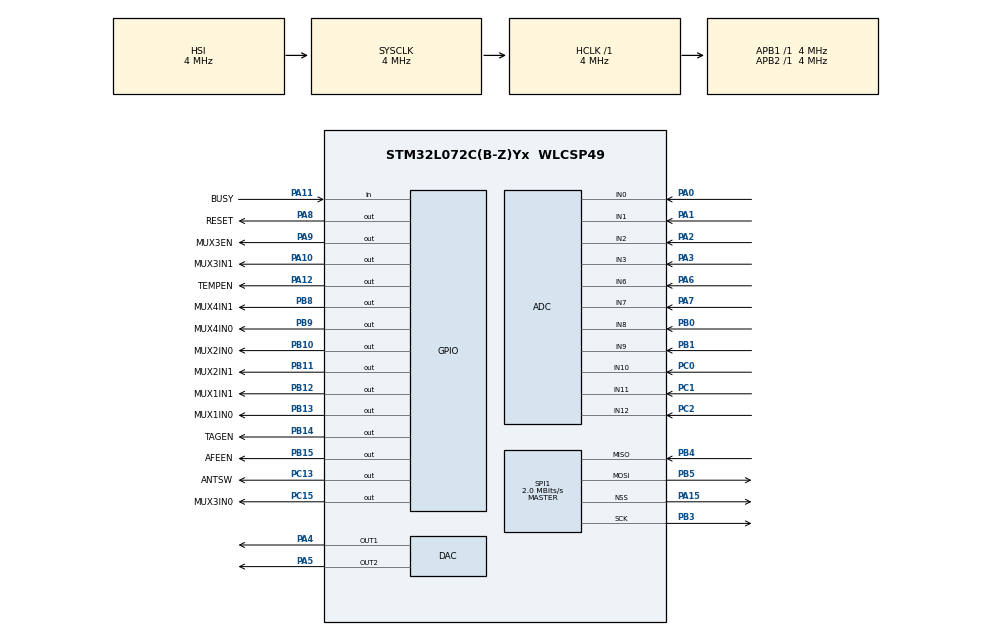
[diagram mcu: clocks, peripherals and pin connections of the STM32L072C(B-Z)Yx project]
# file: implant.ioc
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Mcu.Family=STM32L0
Mcu.Name=STM32L072C(B-Z)Yx
Mcu.Package=WLCSP49
PA0.Mode=IN0
PA0.Signal=ADC_IN0
PA1.Mode=IN1
PA1.Signal=ADC_IN1
PA10.GPIO_Label=MUX3IN1
PA10.Signal=GPIO_Output
PA11.GPIO_Label=BUSY
PA11.Signal=GPIO_Input
PA12.GPIO_Label=TEMPEN
PA12.Signal=GPIO_Output
PA13.Mode=Serial_Wire
PA13.Signal=SYS_SWDIO
PA14.Mode=Serial_Wire
PA14.Signal=SYS_SWCLK
PA15.Mode=NSS_Signal_Hard_Output
PA15.Signal=SPI1_NSS
PA2.Mode=IN2
PA2.Signal=ADC_IN2
PA3.Mode=IN3
PA3.Signal=ADC_IN3
PA4.Signal=COMP_DAC1_group
PA5.Signal=COMP_DAC2_group
PA6.Mode=IN6
PA6.Signal=ADC_IN6
PA7.Mode=IN7
PA7.Signal=ADC_IN7
PA8.GPIO_Label=RESET
PA8.Signal=GPIO_Output
PA9.GPIO_Label=MUX3EN
PA9.Signal=GPIO_Output
PB0.Mode=IN8
PB0.Signal=ADC_IN8
PB1.Mode=IN9
PB1.Signal=ADC_IN9
PB10.GPIO_Label=MUX2IN0
PB10.Signal=GPIO_Output
PB11.GPIO_Label=MUX2IN1
PB11.Signal=GPIO_Output
PB12.GPIO_Label=MUX1IN1
PB12.Signal=GPIO_Output
PB13.GPIO_Label=MUX1IN0
PB13.Signal=GPIO_Output
PB14.GPIO_Label=TAGEN
PB14.GPIO_ModeDefaultOutputPP=GPIO_MODE_OUTPUT_OD
PB14.PinState=GPIO_PIN_SET
PB14.Signal=GPIO_Output
PB15.GPIO_Label=AFEEN
PB15.Signal=GPIO_Output
PB3.Mode=Full_Duplex_Master
PB3.Signal=SPI1_SCK
PB4.Mode=Full_Duplex_Master
PB4.Signal=SPI1_MISO
PB5.Mode=Full_Duplex_Master
PB5.Signal=SPI1_MOSI
PB8.GPIO_Label=MUX4IN1
PB8.Signal=GPIO_Output
PB9.GPIO_Label=MUX4IN0
PB9.Signal=GPIO_Output
PC0.Mode=IN10
PC0.Signal=ADC_IN10
PC1.Mode=IN11
PC1.Signal=ADC_IN11
PC13.GPIO_Label=ANTSW
PC13.Signal=GPIO_Output
PC15-OSC32_OUT.GPIO_Label=MUX3IN0
PC15-OSC32_OUT.Signal=GPIO_Output
PC2.Mode=IN12
PC2.Signal=ADC_IN12
ProjectManager.HeapSize=0x200
ProjectManager.StackSize=0x400
ProjectManager.TargetToolchain=Makefile
RCC.ADCFreq_Value=4000000
RCC.AHBFreq_Value=4000000
RCC.APB1Freq_Value=4000000
RCC.APB1TimFreq_Value=4000000
RCC.APB2Freq_Value=4000000
RCC.APB2TimFreq_Value=4000000
RCC.HCLKFreq_Value=4000000
RCC.HSE_VALUE=8000000
RCC.HSI16_VALUE=16000000
RCC.HSI48_VALUE=48000000
RCC.HSIRCDiv=4
RCC.HSI_VALUE=4000000
RCC.LSE_VALUE=32768
RCC.MSI_VALUE=2097000
RCC.SYSCLKFreq_VALUE=4000000
RCC.SYSCLKSource=RCC_SYSCLKSOURCE_HSI
RCC.VCOOutputFreq_Value=12000000
SH.COMP_DAC1_group.0=DAC_OUT1,DAC_OUT1
SH.COMP_DAC2_group.0=DAC_OUT2,DAC_OUT2
SPI1.CalculateBaudRate=2.0 MBits/s
SPI1.Direction=SPI_DIRECTION_2LINES
SPI1.Mode=SPI_MODE_MASTER
SPI1.VirtualNSS=VM_NSSHARD
SPI1.VirtualType=VM_MASTER
board=implant

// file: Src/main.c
/**
  ******************************************************************************
  * File Name          : main.c
  * Description        : Main program body
  ******************************************************************************
  ** This notice applies to any and all portions of this file
  * that are not between comment pairs USER CODE BEGIN and
  * USER CODE END. Other portions of this file, whether
  * inserted by the user or by software development tools
  * are owned by their respective copyright owners.
  *
  * COPYRIGHT(c) 2019 STMicroelectronics
  *
  * Redistribution and use in source and binary forms, with or without modification,
  * are permitted provided that the following conditions are met:
  *   1. Redistributions of source code must retain the above copyright notice,
  *      this list of conditions and the following disclaimer.
  *   2. Redistributions in binary form must reproduce the above copyright notice,
  *      this list of conditions and the following disclaimer in the documentation
  *      and/or other materials provided with the distribution.
  *   3. Neither the name of STMicroelectronics nor the names of its contributors
  *      may be used to endorse or promote products derived from this software
  *      without specific prior written permission.
  *
  * THIS SOFTWARE IS PROVIDED BY THE COPYRIGHT HOLDERS AND CONTRIBUTORS "AS IS"
  * AND ANY EXPRESS OR IMPLIED WARRANTIES, INCLUDING, BUT NOT LIMITED TO, THE
  * IMPLIED WARRANTIES OF MERCHANTABILITY AND FITNESS FOR A PARTICULAR PURPOSE ARE
  * DISCLAIMED. IN NO EVENT SHALL THE COPYRIGHT HOLDER OR CONTRIBUTORS BE LIABLE
  * FOR ANY DIRECT, INDIRECT, INCIDENTAL, SPECIAL, EXEMPLARY, OR CONSEQUENTIAL
  * DAMAGES (INCLUDING, BUT NOT LIMITED TO, PROCUREMENT OF SUBSTITUTE GOODS OR
  * SERVICES; LOSS OF USE, DATA, OR PROFITS; OR BUSINESS INTERRUPTION) HOWEVER
  * CAUSED AND ON ANY THEORY OF LIABILITY, WHETHER IN CONTRACT, STRICT LIABILITY,
  * OR TORT (INCLUDING NEGLIGENCE OR OTHERWISE) ARISING IN ANY WAY OUT OF THE USE
  * OF THIS SOFTWARE, EVEN IF ADVISED OF THE POSSIBILITY OF SUCH DAMAGE.
  *
  ******************************************************************************
  */
#include "main.h"
#include "stm32l0xx_hal.h"

ADC_HandleTypeDef hadc;

DAC_HandleTypeDef hdac;

SPI_HandleTypeDef hspi1;

/* USER CODE BEGIN PV */
/* Private variables ---------------------------------------------------------*/

/* USER CODE END PV */

void SystemClock_Config(void);
static void MX_GPIO_Init(void);
static void MX_ADC_Init(void);
static void MX_DAC_Init(void);
static void MX_SPI1_Init(void);

/* USER CODE BEGIN PFP */
/* Private function prototypes -----------------------------------------------*/

/* USER CODE END PFP */

int main(void)
{

  /* MCU Configuration----------------------------------------------------------*/

  /* Reset of all peripherals, Initializes the Flash interface and the Systick. */
  HAL_Init();

  /* Configure the system clock */
  SystemClock_Config();

  /* Initialize all configured peripherals */
  MX_GPIO_Init();
  MX_ADC_Init();
  MX_DAC_Init();
  MX_SPI1_Init();

  /* USER CODE BEGIN 2 */

  /*##-3- Set DAC Channel1 DHR register ######################################*/
  HAL_DAC_SetValue(&hdac, DAC_CHANNEL_1, DAC_ALIGN_8B_R, 50);

  /*##-4- Enable DAC Channel1 ################################################*/
  HAL_DAC_Start(&hdac, DAC_CHANNEL_1);

  HAL_GPIO_WritePin(AFEEN_GPIO_Port, AFEEN_Pin, 1);

  /* USER CODE END 2 */

  /* Infinite loop */
  /* USER CODE BEGIN WHILE */
  uint8_t value = 0;
  while (1)
  {
    value++;
    if (value >= 255) {
      value = 0;
      HAL_GPIO_WritePin(AFEEN_GPIO_Port, AFEEN_Pin, 0);
      HAL_Delay(2000);
      HAL_GPIO_WritePin(AFEEN_GPIO_Port, AFEEN_Pin, 1);
    }
    HAL_DAC_SetValue(&hdac, DAC_CHANNEL_1, DAC_ALIGN_8B_R, value);
  /* USER CODE END WHILE */
    //HAL_GPIO_WritePin(AFEEN_GPIO_Port, AFEEN_Pin, 1);
    HAL_Delay(50);
    //HAL_GPIO_WritePin(AFEEN_GPIO_Port, AFEEN_Pin, 0);
    //HAL_Delay(1000);

  }

}

/** System Clock Configuration
*/
void SystemClock_Config(void)
{

  RCC_OscInitTypeDef RCC_OscInitStruct;
  RCC_ClkInitTypeDef RCC_ClkInitStruct;

    /**Configure the main internal regulator output voltage
    */
  __HAL_PWR_VOLTAGESCALING_CONFIG(PWR_REGULATOR_VOLTAGE_SCALE1);

    /**Initializes the CPU, AHB and APB busses clocks
    */
  RCC_OscInitStruct.OscillatorType = RCC_OSCILLATORTYPE_HSI;
  RCC_OscInitStruct.HSIState = RCC_HSI_DIV4;
  RCC_OscInitStruct.HSICalibrationValue = 16;
  RCC_OscInitStruct.PLL.PLLState = RCC_PLL_NONE;
  if (HAL_RCC_OscConfig(&RCC_OscInitStruct) != HAL_OK)
  {
    _Error_Handler(__FILE__, __LINE__);
  }

    /**Initializes the CPU, AHB and APB busses clocks
    */
  RCC_ClkInitStruct.ClockType = RCC_CLOCKTYPE_HCLK|RCC_CLOCKTYPE_SYSCLK
                              |RCC_CLOCKTYPE_PCLK1|RCC_CLOCKTYPE_PCLK2;
  RCC_ClkInitStruct.SYSCLKSource = RCC_SYSCLKSOURCE_HSI;
  RCC_ClkInitStruct.AHBCLKDivider = RCC_SYSCLK_DIV1;
  RCC_ClkInitStruct.APB1CLKDivider = RCC_HCLK_DIV1;
  RCC_ClkInitStruct.APB2CLKDivider = RCC_HCLK_DIV1;

  if (HAL_RCC_ClockConfig(&RCC_ClkInitStruct, FLASH_LATENCY_0) != HAL_OK)
  {
    _Error_Handler(__FILE__, __LINE__);
  }

    /**Configure the Systick interrupt time
    */
  HAL_SYSTICK_Config(HAL_RCC_GetHCLKFreq()/1000);

    /**Configure the Systick
    */
  HAL_SYSTICK_CLKSourceConfig(SYSTICK_CLKSOURCE_HCLK);

  /* SysTick_IRQn interrupt configuration */
  HAL_NVIC_SetPriority(SysTick_IRQn, 0, 0);
}

/* ADC init function */
static void MX_ADC_Init(void)
{

  ADC_ChannelConfTypeDef sConfig;

    /**Configure the global features of the ADC (Clock, Resolution, Data Alignment and number of conversion)
    */
  hadc.Instance = ADC1;
  hadc.Init.OversamplingMode = DISABLE;
  hadc.Init.ClockPrescaler = ADC_CLOCK_SYNC_PCLK_DIV1;
  hadc.Init.Resolution = ADC_RESOLUTION_12B;
  hadc.Init.SamplingTime = ADC_SAMPLETIME_1CYCLE_5;
  hadc.Init.ScanConvMode = ADC_SCAN_DIRECTION_FORWARD;
  hadc.Init.DataAlign = ADC_DATAALIGN_RIGHT;
  hadc.Init.ContinuousConvMode = DISABLE;
  hadc.Init.DiscontinuousConvMode = DISABLE;
  hadc.Init.ExternalTrigConvEdge = ADC_EXTERNALTRIGCONVEDGE_NONE;
  hadc.Init.ExternalTrigConv = ADC_SOFTWARE_START;
  hadc.Init.DMAContinuousRequests = DISABLE;
  hadc.Init.EOCSelection = ADC_EOC_SINGLE_CONV;
  hadc.Init.Overrun = ADC_OVR_DATA_PRESERVED;
  hadc.Init.LowPowerAutoWait = DISABLE;
  hadc.Init.LowPowerFrequencyMode = DISABLE;
  hadc.Init.LowPowerAutoPowerOff = DISABLE;
  if (HAL_ADC_Init(&hadc) != HAL_OK)
  {
    _Error_Handler(__FILE__, __LINE__);
  }

    /**Configure for the selected ADC regular channel to be converted.
    */
  sConfig.Channel = ADC_CHANNEL_0;
  sConfig.Rank = ADC_RANK_CHANNEL_NUMBER;
  if (HAL_ADC_ConfigChannel(&hadc, &sConfig) != HAL_OK)
  {
    _Error_Handler(__FILE__, __LINE__);
  }

    /**Configure for the selected ADC regular channel to be converted.
    */
  sConfig.Channel = ADC_CHANNEL_1;
  if (HAL_ADC_ConfigChannel(&hadc, &sConfig) != HAL_OK)
  {
    _Error_Handler(__FILE__, __LINE__);
  }

    /**Configure for the selected ADC regular channel to be converted.
    */
  sConfig.Channel = ADC_CHANNEL_2;
  if (HAL_ADC_ConfigChannel(&hadc, &sConfig) != HAL_OK)
  {
    _Error_Handler(__FILE__, __LINE__);
  }

    /**Configure for the selected ADC regular channel to be converted.
    */
  sConfig.Channel = ADC_CHANNEL_3;
  if (HAL_ADC_ConfigChannel(&hadc, &sConfig) != HAL_OK)
  {
    _Error_Handler(__FILE__, __LINE__);
  }

    /**Configure for the selected ADC regular channel to be converted.
    */
  sConfig.Channel = ADC_CHANNEL_6;
  if (HAL_ADC_ConfigChannel(&hadc, &sConfig) != HAL_OK)
  {
    _Error_Handler(__FILE__, __LINE__);
  }

    /**Configure for the selected ADC regular channel to be converted.
    */
  sConfig.Channel = ADC_CHANNEL_7;
  if (HAL_ADC_ConfigChannel(&hadc, &sConfig) != HAL_OK)
  {
    _Error_Handler(__FILE__, __LINE__);
  }

    /**Configure for the selected ADC regular channel to be converted.
    */
  sConfig.Channel = ADC_CHANNEL_8;
  if (HAL_ADC_ConfigChannel(&hadc, &sConfig) != HAL_OK)
  {
    _Error_Handler(__FILE__, __LINE__);
  }

    /**Configure for the selected ADC regular channel to be converted.
    */
  sConfig.Channel = ADC_CHANNEL_9;
  if (HAL_ADC_ConfigChannel(&hadc, &sConfig) != HAL_OK)
  {
    _Error_Handler(__FILE__, __LINE__);
  }

    /**Configure for the selected ADC regular channel to be converted.
    */
  sConfig.Channel = ADC_CHANNEL_10;
  if (HAL_ADC_ConfigChannel(&hadc, &sConfig) != HAL_OK)
  {
    _Error_Handler(__FILE__, __LINE__);
  }

    /**Configure for the selected ADC regular channel to be converted.
    */
  sConfig.Channel = ADC_CHANNEL_11;
  if (HAL_ADC_ConfigChannel(&hadc, &sConfig) != HAL_OK)
  {
    _Error_Handler(__FILE__, __LINE__);
  }

    /**Configure for the selected ADC regular channel to be converted.
    */
  sConfig.Channel = ADC_CHANNEL_12;
  if (HAL_ADC_ConfigChannel(&hadc, &sConfig) != HAL_OK)
  {
    _Error_Handler(__FILE__, __LINE__);
  }

}

/* DAC init function */
static void MX_DAC_Init(void)
{

  DAC_ChannelConfTypeDef sConfig;

    /**DAC Initialization
    */
  hdac.Instance = DAC;
  if (HAL_DAC_Init(&hdac) != HAL_OK)
  {
    _Error_Handler(__FILE__, __LINE__);
  }

    /**DAC channel OUT1 config
    */
  sConfig.DAC_Trigger = DAC_TRIGGER_NONE;
  sConfig.DAC_OutputBuffer = DAC_OUTPUTBUFFER_ENABLE;
  if (HAL_DAC_ConfigChannel(&hdac, &sConfig, DAC_CHANNEL_1) != HAL_OK)
  {
    _Error_Handler(__FILE__, __LINE__);
  }

    /**DAC channel OUT2 config
    */
  if (HAL_DAC_ConfigChannel(&hdac, &sConfig, DAC_CHANNEL_2) != HAL_OK)
  {
    _Error_Handler(__FILE__, __LINE__);
  }

}

/* SPI1 init function */
static void MX_SPI1_Init(void)
{

  hspi1.Instance = SPI1;
  hspi1.Init.Mode = SPI_MODE_MASTER;
  hspi1.Init.Direction = SPI_DIRECTION_2LINES;
  hspi1.Init.DataSize = SPI_DATASIZE_8BIT;
  hspi1.Init.CLKPolarity = SPI_POLARITY_LOW;
  hspi1.Init.CLKPhase = SPI_PHASE_1EDGE;
  hspi1.Init.NSS = SPI_NSS_HARD_OUTPUT;
  hspi1.Init.BaudRatePrescaler = SPI_BAUDRATEPRESCALER_2;
  hspi1.Init.FirstBit = SPI_FIRSTBIT_MSB;
  hspi1.Init.TIMode = SPI_TIMODE_DISABLE;
  hspi1.Init.CRCCalculation = SPI_CRCCALCULATION_DISABLE;
  hspi1.Init.CRCPolynomial = 7;
  if (HAL_SPI_Init(&hspi1) != HAL_OK)
  {
    _Error_Handler(__FILE__, __LINE__);
  }

}

/** Configure pins as
        * Analog
        * Input
        * Output
        * EVENT_OUT
        * EXTI
*/
static void MX_GPIO_Init(void)
{

  GPIO_InitTypeDef GPIO_InitStruct;

  /* GPIO Ports Clock Enable */
  __HAL_RCC_GPIOA_CLK_ENABLE();
  __HAL_RCC_GPIOB_CLK_ENABLE();
  __HAL_RCC_GPIOC_CLK_ENABLE();

  /*Configure GPIO pin Output Level */
  HAL_GPIO_WritePin(GPIOB, MUX4IN0_Pin|MUX4IN1_Pin|AFEEN_Pin|MUX1IN0_Pin
                          |MUX2IN1_Pin|MUX1IN1_Pin|MUX2IN0_Pin, GPIO_PIN_RESET);

  /*Configure GPIO pin Output Level */
  HAL_GPIO_WritePin(GPIOA, TEMPEN_Pin|MUX3IN1_Pin|RESET_Pin|MUX3EN_Pin, GPIO_PIN_RESET);

  /*Configure GPIO pin Output Level */
  HAL_GPIO_WritePin(GPIOC, ANTSW_Pin|MUX3IN0_Pin, GPIO_PIN_RESET);

  /*Configure GPIO pin Output Level */
  HAL_GPIO_WritePin(TAGEN_GPIO_Port, TAGEN_Pin, GPIO_PIN_SET);

  /*Configure GPIO pins : MUX4IN0_Pin MUX4IN1_Pin AFEEN_Pin MUX1IN0_Pin
                           MUX2IN1_Pin MUX1IN1_Pin MUX2IN0_Pin */
  GPIO_InitStruct.Pin = MUX4IN0_Pin|MUX4IN1_Pin|AFEEN_Pin|MUX1IN0_Pin
                          |MUX2IN1_Pin|MUX1IN1_Pin|MUX2IN0_Pin;
  GPIO_InitStruct.Mode = GPIO_MODE_OUTPUT_PP;
  GPIO_InitStruct.Pull = GPIO_NOPULL;
  GPIO_InitStruct.Speed = GPIO_SPEED_FREQ_LOW;
  HAL_GPIO_Init(GPIOB, &GPIO_InitStruct);

  /*Configure GPIO pins : TEMPEN_Pin MUX3IN1_Pin RESET_Pin MUX3EN_Pin */
  GPIO_InitStruct.Pin = TEMPEN_Pin|MUX3IN1_Pin|RESET_Pin|MUX3EN_Pin;
  GPIO_InitStruct.Mode = GPIO_MODE_OUTPUT_PP;
  GPIO_InitStruct.Pull = GPIO_NOPULL;
  GPIO_InitStruct.Speed = GPIO_SPEED_FREQ_LOW;
  HAL_GPIO_Init(GPIOA, &GPIO_InitStruct);

  /*Configure GPIO pins : ANTSW_Pin MUX3IN0_Pin */
  GPIO_InitStruct.Pin = ANTSW_Pin|MUX3IN0_Pin;
  GPIO_InitStruct.Mode = GPIO_MODE_OUTPUT_PP;
  GPIO_InitStruct.Pull = GPIO_NOPULL;
  GPIO_InitStruct.Speed = GPIO_SPEED_FREQ_LOW;
  HAL_GPIO_Init(GPIOC, &GPIO_InitStruct);

  /*Configure GPIO pin : BUSY_Pin */
  GPIO_InitStruct.Pin = BUSY_Pin;
  GPIO_InitStruct.Mode = GPIO_MODE_INPUT;
  GPIO_InitStruct.Pull = GPIO_NOPULL;
  HAL_GPIO_Init(BUSY_GPIO_Port, &GPIO_InitStruct);

  /*Configure GPIO pin : TAGEN_Pin */
  GPIO_InitStruct.Pin = TAGEN_Pin;
  GPIO_InitStruct.Mode = GPIO_MODE_OUTPUT_OD;
  GPIO_InitStruct.Pull = GPIO_NOPULL;
  GPIO_InitStruct.Speed = GPIO_SPEED_FREQ_LOW;
  HAL_GPIO_Init(TAGEN_GPIO_Port, &GPIO_InitStruct);

}

void _Error_Handler(char * file, int line)
{
  while(1)
  {
  }
}

/************************ (C) COPYRIGHT STMicroelectronics *****END OF FILE****/
